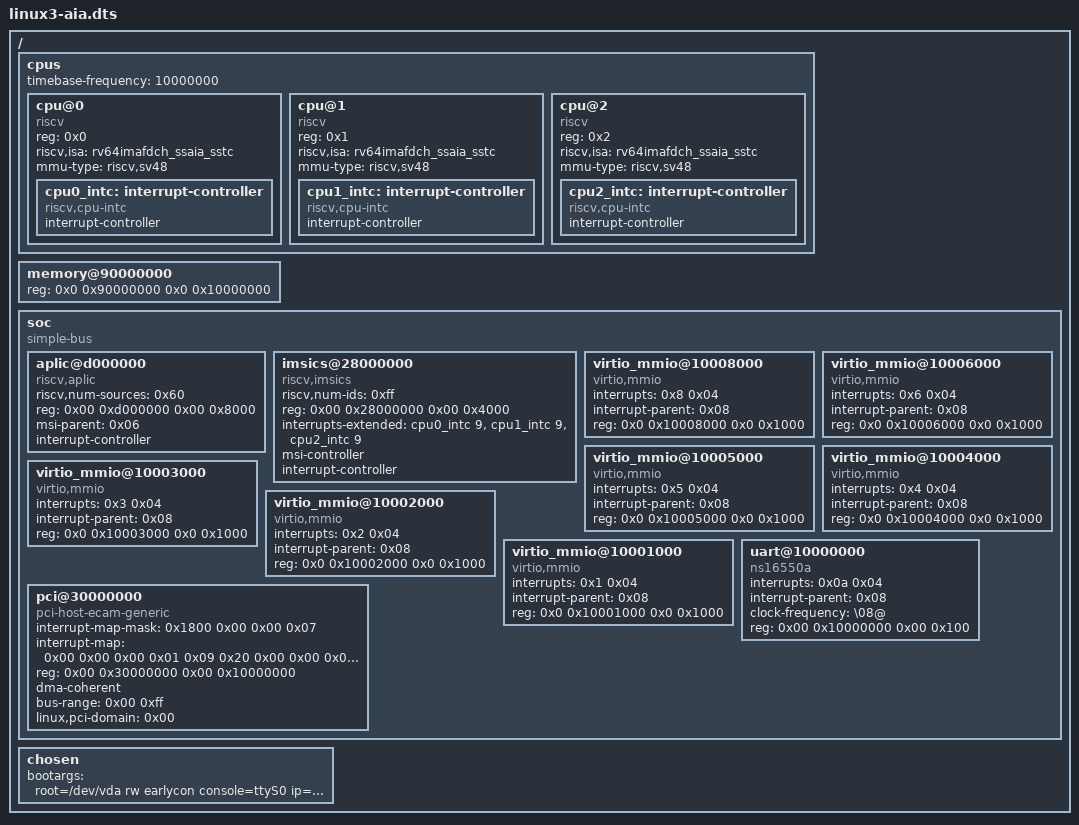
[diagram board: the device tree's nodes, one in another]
/dts-v1/;

/ {
	#address-cells = <0x2>;
	#size-cells = <0x2>;

	cpus {
		#address-cells = <0x1>;
		#size-cells = <0x0>;
		timebase-frequency = <10000000>;
		cpu@0 {
			device_type = "cpu";
			reg = <0x0>;
			status = "okay";
			compatible = "riscv";
			riscv,isa = "rv64imafdch_ssaia_sstc";
			mmu-type = "riscv,sv48";

			cpu0_intc: interrupt-controller {
				#interrupt-cells = <0x1>;
				interrupt-controller;
				compatible = "riscv,cpu-intc";
                phandle = <0x04>;
			};
		};
		cpu@1 {
			device_type = "cpu";
			reg = <0x1>;
			status = "okay";
			compatible = "riscv";
			riscv,isa = "rv64imafdch_ssaia_sstc";
			mmu-type = "riscv,sv48";

			cpu1_intc: interrupt-controller {
				#interrupt-cells = <0x1>;
				interrupt-controller;
				compatible = "riscv,cpu-intc";
			};
		};
		cpu@2 {
			device_type = "cpu";
			reg = <0x2>;
			status = "okay";
			compatible = "riscv";
			riscv,isa = "rv64imafdch_ssaia_sstc";
			mmu-type = "riscv,sv48";

			cpu2_intc: interrupt-controller {
				#interrupt-cells = <0x1>;
				interrupt-controller;
				compatible = "riscv,cpu-intc";
			};
		};
	};

	memory@90000000 {
		device_type = "memory";
		reg = <0x0 0x90000000 0x0 0x10000000>;
	};
soc{
	#address-cells = <0x02>;
	#size-cells = <0x02>;
	compatible = "simple-bus";
	ranges;
		
	aplic@d000000 {
		phandle = <0x08>;
		riscv,num-sources = <0x60>;
		reg = <0x00 0xd000000 0x00 0x8000>;
		msi-parent = <0x06>;
		interrupt-controller;
		#interrupt-cells = <0x02>;
		compatible = "riscv,aplic";
	};

	imsics@28000000 {
		phandle = <0x06>;
		riscv,num-ids = <0xff>;
		reg = <0x00 0x28000000 0x00 0x4000>;
		interrupts-extended = <
			&cpu0_intc 9 
			&cpu1_intc 9 
			&cpu2_intc 9
		>;
		msi-controller;
		interrupt-controller;
		#interrupt-cells = <0x00>;
		compatible = "riscv,imsics";
	};
	
	virtio_mmio@10008000 {
		interrupts = <0x8 0x04>;
		interrupt-parent = <0x08>;
		reg = <0x0 0x10008000 0x0 0x1000>;
		compatible = "virtio,mmio";
	};
	virtio_mmio@10006000 {
		interrupts = <0x6 0x04>;
		interrupt-parent = <0x08>;
		reg = <0x0 0x10006000 0x0 0x1000>;
		compatible = "virtio,mmio";
	};
	virtio_mmio@10005000 {
		interrupts = <0x5 0x04>;
		interrupt-parent = <0x08>;
		reg = <0x0 0x10005000 0x0 0x1000>;
		compatible = "virtio,mmio";
	};
	virtio_mmio@10004000 {
		interrupts = <0x4 0x04>;
		interrupt-parent = <0x08>;
		reg = <0x0 0x10004000 0x0 0x1000>;
		compatible = "virtio,mmio";
	};
	virtio_mmio@10003000 {
		interrupts = <0x3 0x04>;
		interrupt-parent = <0x08>;
		reg = <0x0 0x10003000 0x0 0x1000>;
		compatible = "virtio,mmio";
	};
	virtio_mmio@10002000 {
		interrupts = <0x2 0x04>;
		interrupt-parent = <0x08>;
		reg = <0x0 0x10002000 0x0 0x1000>;
		compatible = "virtio,mmio";
	};
	virtio_mmio@10001000 {
		interrupts = <0x1 0x04>;
		interrupt-parent = <0x08>;
		reg = <0x0 0x10001000 0x0 0x1000>;
		compatible = "virtio,mmio";
	};
	pci@30000000 {
			interrupt-map-mask = <0x1800 0x00 0x00 0x07>;
			interrupt-map = <0x00 0x00 0x00 0x01 0x09 0x20 0x00 0x00 0x00 0x02 0x09 0x21 0x00 0x00 0x00 0x03 0x09 0x22 0x00 0x00 0x00 0x04 0x09 0x23 0x800 0x00 0x00 0x01 0x09 0x21 0x800 0x00 0x00 0x02 0x09 0x22 0x800 0x00 0x00 0x03 0x09 0x23 0x800 0x00 0x00 0x04 0x09 0x20 0x1000 0x00 0x00 0x01 0x09 0x22 0x1000 0x00 0x00 0x02 0x09 0x23 0x1000 0x00 0x00 0x03 0x09 0x20 0x1000 0x00 0x00 0x04 0x09 0x21 0x1800 0x00 0x00 0x01 0x09 0x23 0x1800 0x00 0x00 0x02 0x09 0x20 0x1800 0x00 0x00 0x03 0x09 0x21 0x1800 0x00 0x00 0x04 0x09 0x22>;
			ranges = <0x1000000 0x00 0x00 0x00 0x3000000 0x00 0x10000 0x2000000 0x00 0x40000000 0x00 0x40000000 0x00 0x40000000 0x3000000 0x04 0x00 0x04 0x00 0x04 0x00>;
			reg = <0x00 0x30000000 0x00 0x10000000>;
			dma-coherent;
			bus-range = <0x00 0xff>;
			linux,pci-domain = <0x00>;
			device_type = "pci";
			compatible = "pci-host-ecam-generic";
			#size-cells = <0x02>;
			#interrupt-cells = <0x01>;
			#address-cells = <0x03>;
		};
	uart@10000000 {
		interrupts = <0x0a 0x04>;
		interrupt-parent = <0x08>;
		clock-frequency = "\08@";
		reg = <0x00 0x10000000 0x00 0x100>;
		compatible = "ns16550a";
	};

};
	chosen {
		bootargs = "root=/dev/vda rw earlycon console=ttyS0 ip=192.168.42.15";
	};
};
